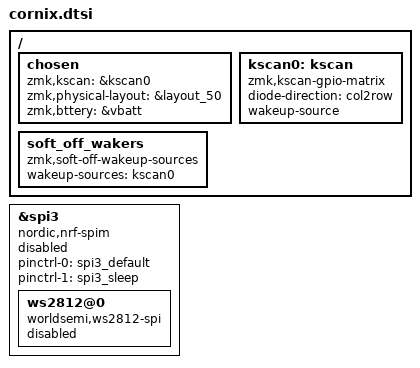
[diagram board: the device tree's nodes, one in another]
#include <dt-bindings/led/led.h>
#include "../common/cornix-layout.dtsi"
#include "../common/cornix-sensor.dtsi"

/ {
    chosen {
        zmk,kscan = &kscan0;
        zmk,physical-layout = &layout_50;
        zmk,bttery = &vbatt;
    };

    kscan0: kscan {
        compatible = "zmk,kscan-gpio-matrix";
        diode-direction = "col2row";
        wakeup-source;
    };

    soft_off_wakers {
        compatible = "zmk,soft-off-wakeup-sources";
        wakeup-sources = <&kscan0>;
    };
};

&spi3 {
    status = "disabled";
    compatible = "nordic,nrf-spim";

    pinctrl-0 = <&spi3_default>;
    pinctrl-1 = <&spi3_sleep>;
    pinctrl-names = "default", "sleep";

    ws2812@0 {
        status = "disabled";
        compatible = "worldsemi,ws2812-spi";
    };
};
